# STM32H747_CM4 register map
File version: 2.3
CPU: CM4 r0p1, little endian, MPU, FPU, 4 interrupt priority bits
Registers are 32-bit, read-write, reset 0x0 unless marked. A register's access mark holds for its fields unless they carry their own. Offsets are from the block's base; [hi:lo] are bit positions.

## OTG1_HS_PWRCLK — USB 1 on the go high speed
Base 0x40040E00
Same registers: OTG2_HS_PWRCLK 0x40080E00
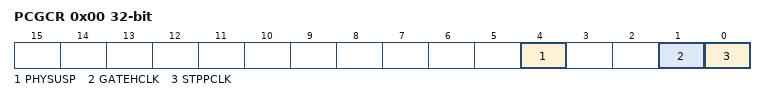
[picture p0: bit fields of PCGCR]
0x00 PCGCR — Power and clock gating control register
  [4] PHYSUSP — PHY suspended
  [1] GATEHCLK
  [0] STPPCLK — Stop PHY clock

## Ethernet_MTL
Base 0x40028C00
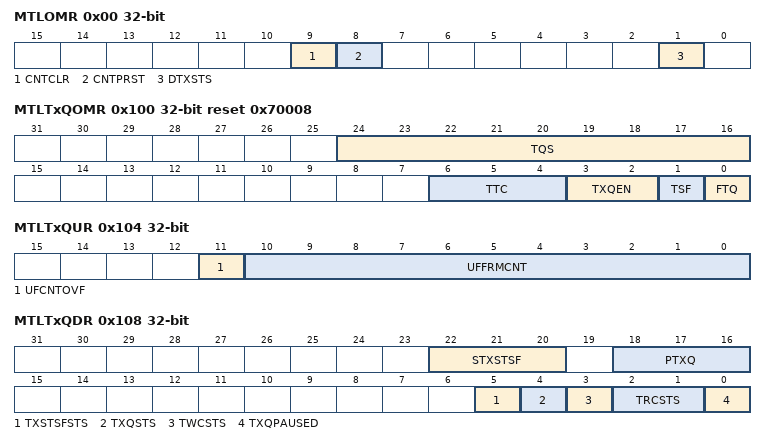
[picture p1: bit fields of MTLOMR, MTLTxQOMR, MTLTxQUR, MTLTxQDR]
0x00 MTLOMR access not given — Operating mode Register
  [9] CNTCLR — Counters Reset
  [8] CNTPRST — Counters Preset
  [1] DTXSTS — Drop Transmit Status
0x20 MTLISR access not given — Interrupt status Register
  [0] Q0IS — Queue interrupt status
0x100 MTLTxQOMR access not given reset 0x70008 — Tx queue operating mode Register
  [24:16] TQS — Transmit Queue Size
  [6:4] TTC — Transmit Threshold Control
  [3:2] TXQEN — Transmit Queue Enable
  [1] TSF — Transmit Store and Forward
  [0] FTQ — Flush Transmit Queue
0x104 MTLTxQUR access not given — Tx queue underflow register
  [11] UFCNTOVF — Overflow Bit for Underflow Packet Counter
  [10:0] UFFRMCNT — Underflow Packet Counter
0x108 MTLTxQDR access not given — Tx queue debug Register
  [22:20] STXSTSF — Number of Status Words in Tx Status FIFO of Queue
  [18:16] PTXQ — Number of Packets in the Transmit Queue
  [5] TXSTSFSTS — MTL Tx Status FIFO Full Status
  [4] TXQSTS — MTL Tx Queue Not Empty Status
  [3] TWCSTS — MTL Tx Queue Write Controller Status
  [2:1] TRCSTS — MTL Tx Queue Read Controller Status
  [0] TXQPAUSED — Transmit Queue in Pause
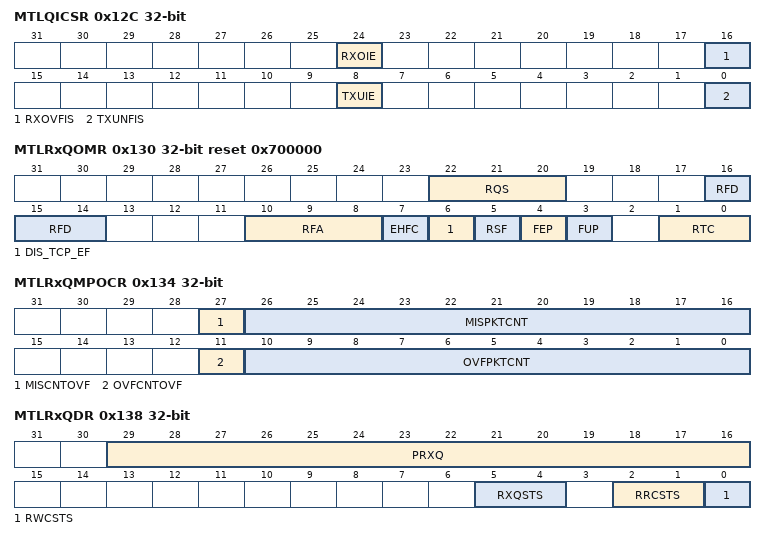
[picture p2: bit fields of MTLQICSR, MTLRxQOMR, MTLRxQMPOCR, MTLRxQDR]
0x12C MTLQICSR access not given — Queue interrupt control status Register
  [24] RXOIE — Receive Queue Overflow Interrupt Enable
  [16] RXOVFIS — Receive Queue Overflow Interrupt Status
  [8] TXUIE — Transmit Queue Underflow Interrupt Enable
  [0] TXUNFIS — Transmit Queue Underflow Interrupt Status
0x130 MTLRxQOMR access not given reset 0x700000 — Rx queue operating mode register
  [22:20] RQS — Receive Queue Size
  [16:14] RFD — Threshold for Deactivating Flow Control
  [10:8] RFA — Threshold for Activating Flow Control
  [7] EHFC — Enable Hardware Flow Control
  [6] DIS_TCP_EF — Disable Dropping of TCP
  [5] RSF — Receive Queue Store and Forward
  [4] FEP — Forward Error Packets
  [3] FUP — Forward Undersized Good Packets
  [1:0] RTC — Receive Queue Threshold Control
0x134 MTLRxQMPOCR access not given — Rx queue missed packet and overflow counter register
  [27] MISCNTOVF — Missed Packet Counter Overflow Bit
  [26:16] MISPKTCNT — Missed Packet Counter
  [11] OVFCNTOVF — Overflow Counter Overflow Bit
  [10:0] OVFPKTCNT — Overflow Packet Counter
0x138 MTLRxQDR access not given — Rx queue debug register
  [29:16] PRXQ — Number of Packets in Receive Queue
  [5:4] RXQSTS — MTL Rx Queue Fill-Level Status
  [2:1] RRCSTS — MTL Rx Queue Read Controller State
  [0] RWCSTS — MTL Rx Queue Write Controller Active Status

## CAN_CCU — CCU registers
Base 0x4000A800
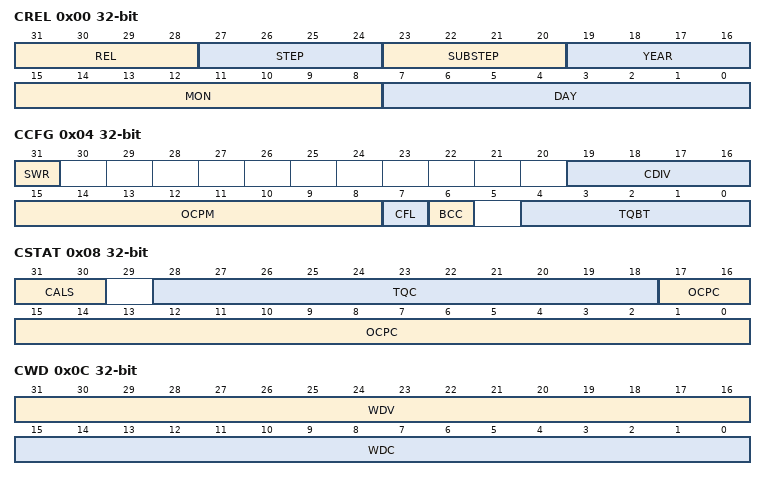
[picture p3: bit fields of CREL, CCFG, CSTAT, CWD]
0x00 CREL — Clock Calibration Unit Core Release Register
  [31:28] REL — Core Release
  [27:24] STEP — Step of Core Release
  [23:20] SUBSTEP — Sub-step of Core Release
  [19:16] YEAR — Time Stamp Year
  [15:8] MON — Time Stamp Month
  [7:0] DAY — Time Stamp Day
0x04 CCFG — Calibration Configuration Register
  [31] SWR — Software Reset
  [19:16] CDIV — Clock Divider
  [15:8] OCPM — Oscillator Clock Periods Minimum
  [7] CFL — Calibration Field Length
  [6] BCC — Bypass Clock Calibration
  [4:0] TQBT — Time Quanta per Bit Time
0x08 CSTAT — Calibration Status Register
  [31:30] CALS — Calibration State
  [28:18] TQC — Time Quanta Counter
  [17:0] OCPC — Oscillator Clock Period Counter
0x0C CWD — Calibration Watchdog Register
  [31:16] WDV, [15:0] WDC
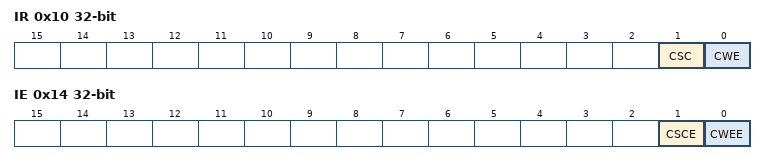
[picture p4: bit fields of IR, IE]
0x10 IR — Clock Calibration Unit Interrupt Register
  [1] CSC — Calibration State Changed
  [0] CWE — Calibration Watchdog Event
0x14 IE — Clock Calibration Unit Interrupt Enable Register
  [1] CSCE — Calibration State Changed Enable
  [0] CWEE — Calibration Watchdog Event Enable
